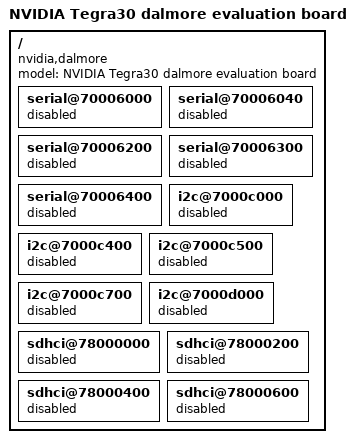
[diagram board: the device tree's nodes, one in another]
/*
 * arch/arm/boot/dts/tegra30-dalmore.dts
 *
 * Copyright (C) 2012-2014 NVIDIA Corporation. All rights reserved.
 *
 * This software is licensed under the terms of the GNU General Public
 * License version 2, as published by the Free Software Foundation, and
 * may be copied, distributed, and modified under those terms.
 *
 * This program is distributed in the hope that it will be useful,
 * but WITHOUT ANY WARRANTY; without even the implied warranty of
 * MERCHANTABILITY or FITNESS FOR A PARTICULAR PURPOSE.  See the
 * GNU General Public License for more details.
 *
 */

/dts-v1/;

/include/ "tegra30.dtsi"

/ {
	model = "NVIDIA Tegra30 dalmore evaluation board";
	compatible = "nvidia,dalmore", "nvidia,tegra30";

	serial@70006000 {
		status = "disable";
	};

	serial@70006040 {
		status = "disable";
	};

	serial@70006200 {
		status = "disable";
	};

	serial@70006300 {
		status = "disable";
	};

	serial@70006400 {
		status = "disable";
	};

	i2c@7000c000 {
		status = "disable";
	};

	i2c@7000c400 {
		status = "disable";
	};

	i2c@7000c500 {
		status = "disable";
	};

	i2c@7000c700 {
		status = "disable";
	};

	i2c@7000d000 {
		status = "disable";
	};

	sdhci@78000000 {
		status = "disable";
	};

	sdhci@78000200 {
		status = "disable";
	};

	sdhci@78000400 {
		status = "disable";
	};

	sdhci@78000600 {
		status = "disable";
	};
};
